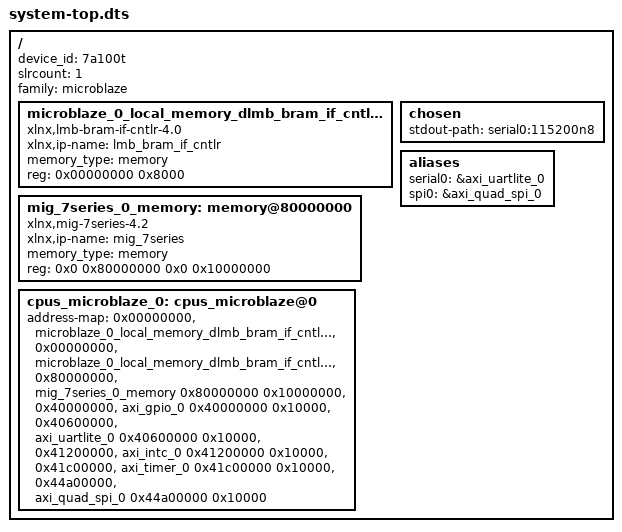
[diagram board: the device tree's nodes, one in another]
/dts-v1/;
#include "pl.dtsi"
/ {
	device_id = "7a100t";
	#address-cells = <1>;
	#size-cells = <1>;
	slrcount = <1>;
	family = "microblaze";
	microblaze_0_local_memory_dlmb_bram_if_cntlr_memory: memory@0 {
		compatible = "xlnx,lmb-bram-if-cntlr-4.0";
		xlnx,ip-name = "lmb_bram_if_cntlr";
		device_type = "memory";
		memory_type = "memory";
		reg = <0x00000000 0x8000>;
	};
	mig_7series_0_memory: memory@80000000 {
		compatible = "xlnx,mig-7series-4.2";
		xlnx,ip-name = "mig_7series";
		device_type = "memory";
		memory_type = "memory";
		reg = <0x0 0x80000000 0x0 0x10000000>;
	};
	chosen {
		stdout-path = "serial0:115200n8";
	};
	aliases {
		serial0 = &axi_uartlite_0;
		spi0 = &axi_quad_spi_0;
	};
	cpus_microblaze_0: cpus_microblaze@0 {
		address-map = <0x00000000 &microblaze_0_local_memory_dlmb_bram_if_cntlr_memory 0x00000000 0x8000>, 
			      <0x00000000 &microblaze_0_local_memory_dlmb_bram_if_cntlr 0x00000000 0x8000>, 
			      <0x80000000 &mig_7series_0_memory 0x80000000 0x10000000>, 
			      <0x40000000 &axi_gpio_0 0x40000000 0x10000>, 
			      <0x40600000 &axi_uartlite_0 0x40600000 0x10000>, 
			      <0x41200000 &axi_intc_0 0x41200000 0x10000>, 
			      <0x41c00000 &axi_timer_0 0x41c00000 0x10000>, 
			      <0x44a00000 &axi_quad_spi_0 0x44a00000 0x10000>;
		#ranges-address-cells = <0x1>;
		#ranges-size-cells = <0x1>;
	};
};
